# SiFive_FU700 register map
File version: 0.1
From SiFive,FU700,model device generator
Registers are 32-bit, read-write, no defined reset value unless marked. A register's access mark holds for its fields unless they carry their own. Offsets are from the block's base; lines under a group give offsets from that group; [hi:lo] are bit positions; {n}, {i} and the like mark numbered series; 'fields as' and 'values as' point back to an identical list; <NAME> marks a mode.

## Memory map
0x00004000 sifive_test0_0 size 0x1000 — From sifive,test0,control peripheral generator
0x02000000 riscv_clint0_0 size 0x10000 — From riscv,clint0,control peripheral generator
0x02010000 sifive_ccache0_0 size 0x4000 — From sifive,ccache0,control peripheral generator
0x0C000000 riscv_plic0_0 size 0x4000000 — From riscv,plic0,control peripheral generator

## sifive_ccache0_0 — From sifive,ccache0,control peripheral generator
Base 0x02010000
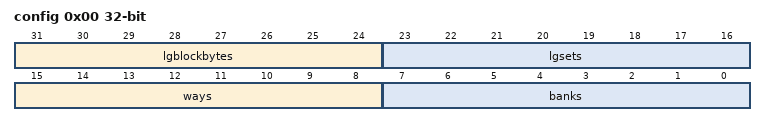
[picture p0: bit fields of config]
0x00 config — Information about the Cache Configuration
  [31:24] lgblockbytes ro — Base-2 logarithm of the bytes per cache block
  [23:16] lgsets ro — Base-2 logarithm of the sets per bank
  [15:8] ways ro — Number of ways per bank
  [7:0] banks ro — Number of banks in the cache
0x08 wayenable — The index of the largest way which has been enabled. May only be increased.
0x2000 l2perfevent0 — The L2 performance event0 control register.
0x2008 l2perfevent1 — The L2 performance event1 control register.
0x2800 l2clientfilter — The L2 Client Filterregister.
0x3000 l2pmcounter0 — The L2 performance monitor counter0 register.
0x3008 l2pmcounter1 — The L2 performance monitor counter1 register.
0x31F8 l2pmcounter63 — The L2 performance monitor counter63 register.

## riscv_clint0_0 — From riscv,clint0,control peripheral generator
Base 0x02000000
{0x0+4i} msip_{i} (i=0..3) — MSIP Register for hart {i}
{0x4000+8i} mtimecmp_{i} 64-bit (i=0..3) — MTIMECMP Register for hart {i}
0xBFF8 mtime 64-bit

## riscv_plic0_0 — From riscv,plic0,control peripheral generator
Base 0x0C000000
{0x0+4i} priority_{i} (i=1..137) — PRIORITY Register for interrupt id {i}
{0x1000+4i} pending_{i} (i=0..3) — PENDING Register for interrupt ids {32i+31} to {32i}
0x1010 pending_4 — PENDING Register for interrupt ids 137 to 128
{0x2000+0x80*i} enable_0_{i} (i=0..3) — ENABLE Register for interrupt ids 31 to 0 for hart {i}
{0x2004+0x80*i} enable_1_{i} (i=0..3) — ENABLE Register for interrupt ids 63 to 32 for hart {i}
{0x2008+0x80*i} enable_2_{i} (i=0..3) — ENABLE Register for interrupt ids 95 to 64 for hart {i}
{0x200C+0x80*i} enable_3_{i} (i=0..3) — ENABLE Register for interrupt ids 127 to 96 for hart {i}
{0x2010+0x80*i} enable_4_{i} (i=0..3) — ENABLE Register for interrupt ids 137 to 128 for hart {i}
{0x200000+0x1000*i} threshold_{i} (i=0..3) — PRIORITY THRESHOLD Register for hart {i}
{0x200004+0x1000*i} claimplete_{i} (i=0..3) — CLAIM and COMPLETE Register for hart {i}

## sifive_test0_0 — From sifive,test0,control peripheral generator
Base 0x00004000
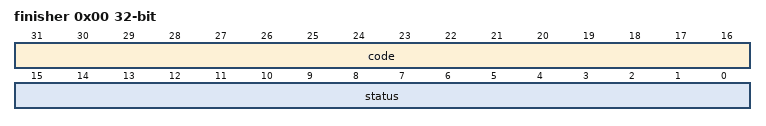
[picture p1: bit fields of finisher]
0x00 finisher — Test finisher register
  [31:16] code — Finisher code
  [15:0] status — Test status
